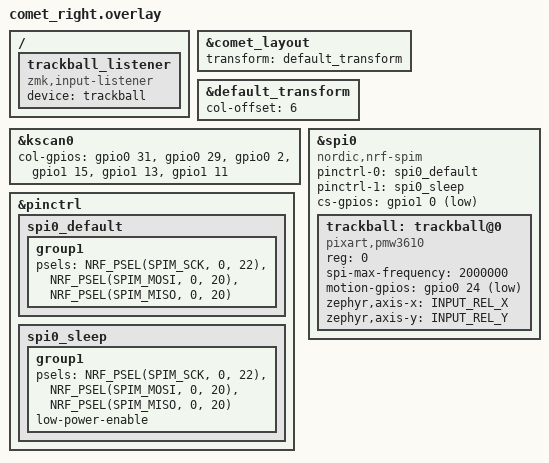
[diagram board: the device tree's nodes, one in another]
#include <dt-bindings/zmk/matrix_transform.h>
#include <zephyr/dt-bindings/input/input-event-codes.h>
#include "comet.dtsi"

&comet_layout {
    transform = <&default_transform>;
};

&default_transform {
    col-offset = <6>;
};

&kscan0 {
    col-gpios
        = <&gpio0 31 GPIO_ACTIVE_HIGH>  // P0.31 (A0/D14) - outer
        , <&gpio0 29 GPIO_ACTIVE_HIGH>  // P0.29 (A1/D15) - pinky
        , <&gpio0 2 GPIO_ACTIVE_HIGH>   // P0.02 (A2/D16) - ring
        , <&gpio1 15 GPIO_ACTIVE_HIGH>  // P1.15 (A3/D17) - middle
        , <&gpio1 13 GPIO_ACTIVE_HIGH>  // P1.13 (D18) - index
        , <&gpio1 11 GPIO_ACTIVE_HIGH>  // P1.10 (D19) - inner
        ;
};

&pinctrl {
    spi0_default: spi0_default {
        group1 {
            psels = <NRF_PSEL(SPIM_SCK, 0, 22)>,
                <NRF_PSEL(SPIM_MOSI, 0, 20)>,
                <NRF_PSEL(SPIM_MISO, 0, 20)>;
        };
    };

    spi0_sleep: spi0_sleep {
        group1 {
            psels = <NRF_PSEL(SPIM_SCK, 0, 22)>,
                <NRF_PSEL(SPIM_MOSI, 0, 20)>,
                <NRF_PSEL(SPIM_MISO, 0, 20)>;
            low-power-enable;
        };
    };
};

&spi0 {
    status = "okay";
    compatible = "nordic,nrf-spim";
    pinctrl-0 = <&spi0_default>;
    pinctrl-1 = <&spi0_sleep>;
    pinctrl-names = "default", "sleep";
    cs-gpios = <&gpio1 0 GPIO_ACTIVE_LOW>;

    trackball: trackball@0 {
        status = "okay";
        compatible = "pixart,pmw3610";
        reg = <0>;
        spi-max-frequency = <2000000>;
        motion-gpios = <&gpio0 24 (GPIO_ACTIVE_LOW | GPIO_PULL_UP)>;
        zephyr,axis-x = <INPUT_REL_X>;
        zephyr,axis-y = <INPUT_REL_Y>;

        /*   optional features   */
        // snipe-layers = <1>;
        // scroll-layers = <2 3>;
        // automouse-layer = <4>;
    };
};

/ {
  trackball_listener {
    compatible = "zmk,input-listener";
    device = <&trackball>;
  };
};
